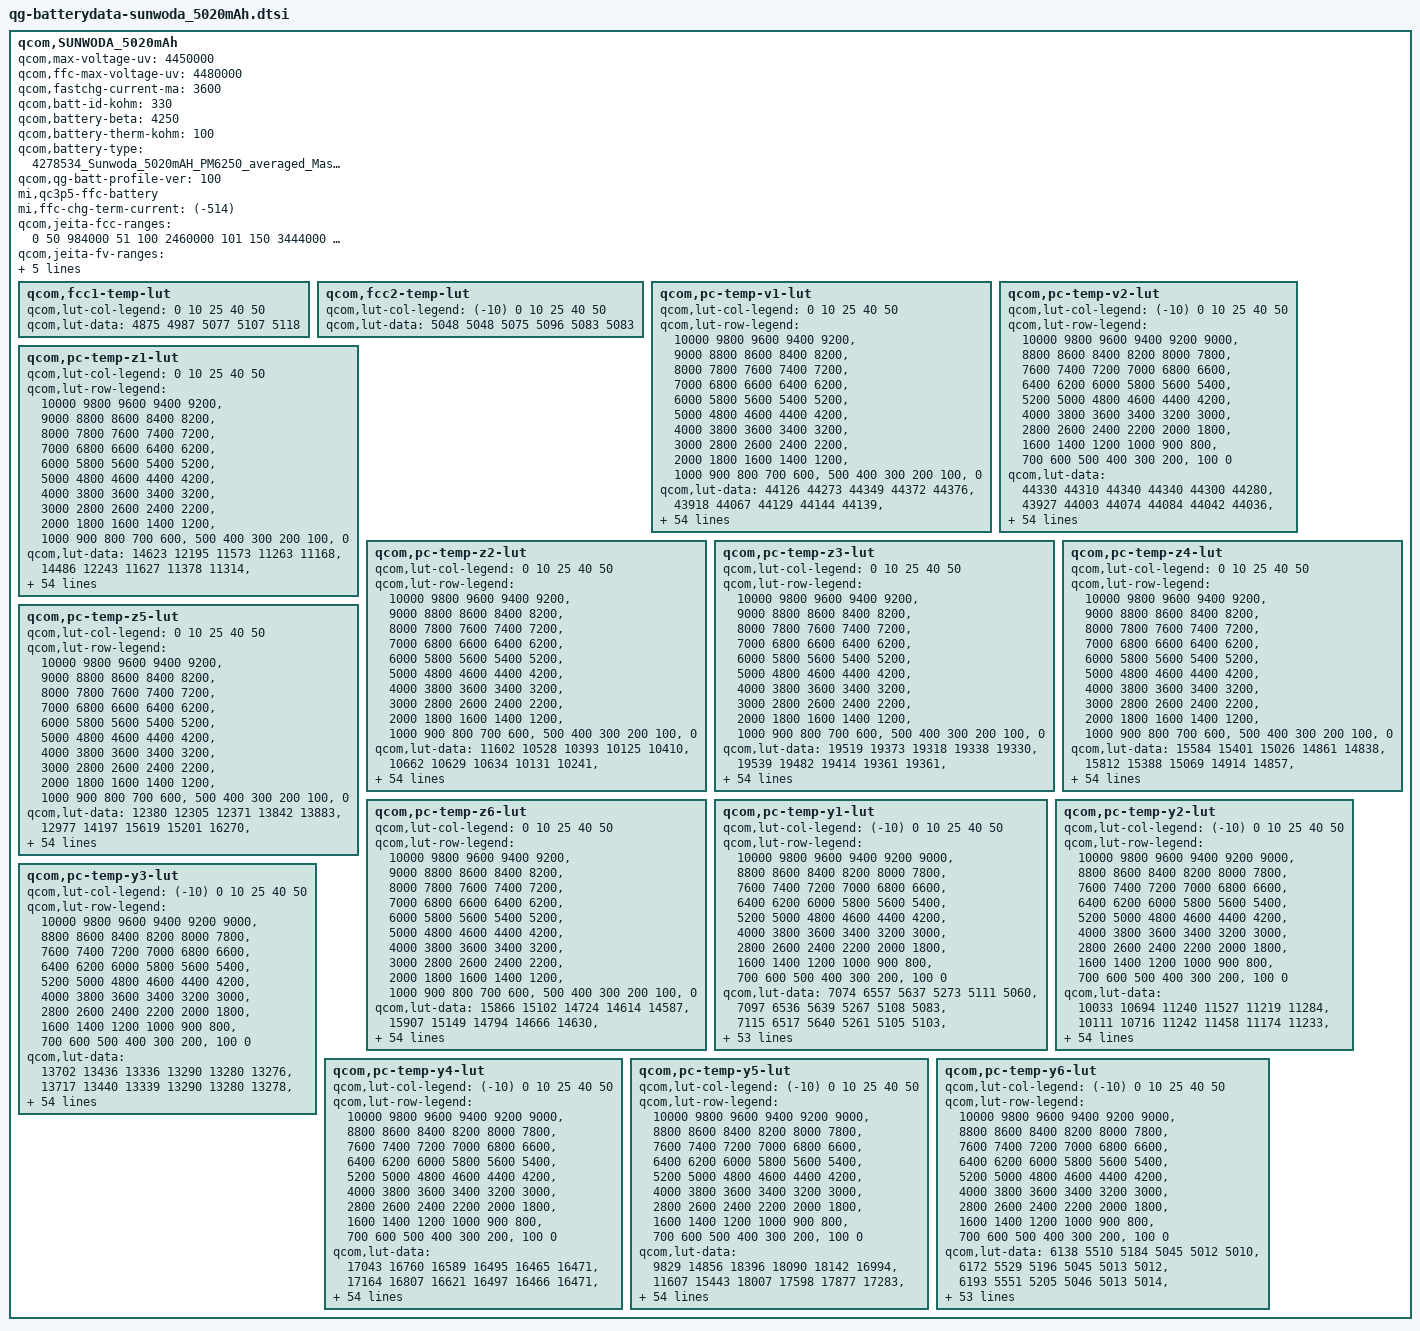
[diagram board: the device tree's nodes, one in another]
/*
 * Copyright (c) 2019, The Linux Foundation. All rights reserved.
 * Copyright (C) 2020 XiaoMi, Inc.
 *
 * This program is free software; you can redistribute it and/or modify
 * it under the terms of the GNU General Public License version 2 and
 * only version 2 as published by the Free Software Foundation.
 *
 * This program is distributed in the hope that it will be useful,
 * but WITHOUT ANY WARRANTY; without even the implied warranty of
 * MERCHANTABILITY or FITNESS FOR A PARTICULAR PURPOSE.  See the
 * GNU General Public License for more details.
 */

qcom,SUNWODA_5020mAh {
	qcom,max-voltage-uv = <4450000>;
	qcom,ffc-max-voltage-uv = <4480000>;
	qcom,fastchg-current-ma = <3600>;
	qcom,batt-id-kohm = <330>;
	qcom,battery-beta = <4250>;
	qcom,battery-therm-kohm = <100>;
	qcom,battery-type =
		"4278534_Sunwoda_5020mAH_PM6250_averaged_MasterSlave_Nov7th2019";
	qcom,qg-batt-profile-ver = <100>;
	mi,qc3p5-ffc-battery;
	mi,ffc-chg-term-current = <(-514)>;
	qcom,jeita-fcc-ranges = <0   50   984000
				 51  100  2460000
				 101 150  3444000
				 151 450  3600000
				 451 600  2460000>;

	qcom,jeita-fv-ranges = <0   50   4450000
				51  100  4450000
				101 150  4450000
				151 450  4480000
				451 600  4100000>;

	qcom,step-chg-ranges = <3001000  4250000  3600000
				4250001  4430000  3300000
				4430001  4450000  3000000>;

	qcom,dynamic-fv-ranges = <0   100  4480000
				 101  200  4460000
				 201  300  4440000
				 301  400  4420000
				 401  500  4400000>;

	qcom,fcc1-temp-lut {
		qcom,lut-col-legend = <0 10 25 40 50>;
		qcom,lut-data = <4875 4987 5077 5107 5118>;
	};

	qcom,fcc2-temp-lut {
		qcom,lut-col-legend = <(-10) 0 10 25 40 50>;
		qcom,lut-data = <5048 5048 5075 5096 5083 5083>;
	};

	qcom,pc-temp-v1-lut {
		qcom,lut-col-legend = <0 10 25 40 50>;
		qcom,lut-row-legend = <10000 9800 9600 9400 9200>,
			<9000 8800 8600 8400 8200>,
			<8000 7800 7600 7400 7200>,
			<7000 6800 6600 6400 6200>,
			<6000 5800 5600 5400 5200>,
			<5000 4800 4600 4400 4200>,
			<4000 3800 3600 3400 3200>,
			<3000 2800 2600 2400 2200>,
			<2000 1800 1600 1400 1200>,
			<1000 900 800 700 600>,
			<500 400 300 200 100>,
			<0>;
		qcom,lut-data = <44126 44273 44349 44372 44376>,
			<43918 44067 44129 44144 44139>,
			<43695 43855 43919 43935 43931>,
			<43465 43639 43710 43727 43728>,
			<43230 43417 43501 43516 43512>,
			<42988 43184 43286 43302 43291>,
			<42744 42939 43049 43072 43061>,
			<42498 42693 42795 42824 42822>,
			<42252 42446 42544 42574 42579>,
			<42013 42199 42296 42327 42334>,
			<41782 41958 42050 42081 42088>,
			<41556 41720 41807 41842 41847>,
			<41335 41488 41567 41609 41609>,
			<41120 41263 41335 41378 41374>,
			<40908 41043 41113 41149 41144>,
			<40698 40830 40898 40926 40919>,
			<40493 40621 40689 40712 40706>,
			<40296 40421 40484 40506 40503>,
			<40106 40238 40290 40310 40309>,
			<39928 40063 40112 40131 40128>,
			<39770 39884 39929 39951 39949>,
			<39617 39705 39710 39731 39735>,
			<39445 39512 39472 39476 39483>,
			<39248 39258 39256 39255 39262>,
			<39054 38973 39052 39074 39089>,
			<38874 38801 38881 38920 38940>,
			<38706 38712 38766 38798 38807>,
			<38596 38643 38674 38697 38688>,
			<38528 38574 38587 38598 38581>,
			<38474 38510 38503 38496 38484>,
			<38425 38450 38424 38400 38395>,
			<38381 38392 38349 38320 38312>,
			<38340 38338 38278 38248 38236>,
			<38300 38287 38217 38181 38163>,
			<38262 38240 38167 38117 38095>,
			<38225 38196 38118 38056 38029>,
			<38190 38160 38069 37997 37962>,
			<38148 38121 38019 37940 37895>,
			<38086 38059 37952 37868 37814>,
			<38004 37966 37863 37773 37711>,
			<37903 37859 37759 37666 37595>,
			<37771 37737 37644 37551 37474>,
			<37623 37595 37511 37420 37341>,
			<37456 37419 37342 37256 37179>,
			<37295 37259 37190 37112 37043>,
			<37218 37158 37097 37029 36966>,
			<37176 37125 37068 36999 36938>,
			<37146 37105 37051 36981 36920>,
			<37114 37079 37029 36962 36899>,
			<37067 37036 36978 36900 36825>,
			<36878 36824 36732 36626 36534>,
			<36429 36373 36289 36175 36087>,
			<35839 35781 35699 35585 35503>,
			<35031 34967 34886 34776 34682>,
			<33735 33660 33609 33497 33378>,
			<30000 30000 30000 30000 30000>;
	};

	qcom,pc-temp-v2-lut {
		qcom,lut-col-legend = <(-10) 0 10 25 40 50>;
		qcom,lut-row-legend = <10000 9800 9600 9400 9200 9000>,
			<8800 8600 8400 8200 8000 7800>,
			<7600 7400 7200 7000 6800 6600>,
			<6400 6200 6000 5800 5600 5400>,
			<5200 5000 4800 4600 4400 4200>,
			<4000 3800 3600 3400 3200 3000>,
			<2800 2600 2400 2200 2000 1800>,
			<1600 1400 1200 1000 900 800>,
			<700 600 500 400 300 200>,
			<100 0>;
		qcom,lut-data = <44330 44310 44340 44340 44300 44280>,
			<43927 44003 44074 44084 44042 44036>,
			<43573 43720 43820 43839 43796 43800>,
			<43276 43463 43584 43608 43564 43573>,
			<43033 43236 43367 43393 43348 43357>,
			<42792 43005 43143 43171 43126 43134>,
			<42532 42756 42903 42933 42888 42896>,
			<42266 42500 42655 42688 42645 42651>,
			<41979 42242 42406 42441 42400 42406>,
			<41652 41981 42155 42192 42154 42159>,
			<41411 41722 41906 41946 41910 41914>,
			<41304 41459 41664 41703 41669 41673>,
			<41220 41208 41425 41463 41432 41435>,
			<41051 41015 41191 41229 41200 41204>,
			<40719 40871 40963 41002 40975 40979>,
			<40359 40705 40745 40781 40756 40760>,
			<40020 40441 40547 40566 40543 40547>,
			<39692 40131 40353 40359 40337 40341>,
			<39430 39869 40142 40164 40145 40149>,
			<39220 39641 39918 39981 39965 39970>,
			<39014 39421 39689 39778 39772 39775>,
			<38767 39200 39447 39533 39544 39545>,
			<38532 38985 39211 39286 39310 39308>,
			<38396 38792 39009 39075 39099 39098>,
			<38311 38614 38829 38885 38900 38901>,
			<38242 38448 38672 38726 38735 38738>,
			<38179 38275 38536 38594 38604 38606>,
			<38123 38120 38414 38479 38490 38492>,
			<38067 38036 38305 38373 38386 38388>,
			<38012 37986 38206 38277 38291 38292>,
			<37958 37944 38112 38188 38205 38206>,
			<37903 37904 38014 38105 38127 38129>,
			<37846 37867 37927 38028 38053 38055>,
			<37784 37823 37865 37957 37978 37980>,
			<37718 37775 37818 37890 37902 37905>,
			<37649 37723 37773 37820 37818 37821>,
			<37580 37669 37733 37747 37722 37723>,
			<37508 37611 37690 37670 37622 37619>,
			<37425 37539 37631 37590 37529 37523>,
			<37331 37451 37556 37505 37438 37428>,
			<37236 37350 37464 37415 37345 37333>,
			<37141 37232 37346 37319 37252 37238>,
			<37051 37106 37212 37199 37138 37126>,
			<36971 36985 37063 37052 36989 36980>,
			<36896 36880 36916 36930 36882 36874>,
			<36816 36784 36825 36879 36838 36832>,
			<36766 36726 36792 36866 36826 36817>,
			<36714 36661 36752 36846 36809 36799>,
			<36652 36595 36694 36811 36779 36765>,
			<36541 36493 36585 36722 36670 36647>,
			<36311 36322 36340 36407 36337 36307>,
			<35881 35966 35877 35885 35817 35764>,
			<35225 35364 35210 35200 35133 35048>,
			<34250 34460 34293 34227 34159 34056>,
			<32677 32962 32764 32652 32768 32603>,
			<30163 28489 27415 27358 27428 27387>;
	};

	qcom,pc-temp-z1-lut {
		qcom,lut-col-legend = <0 10 25 40 50>;
		qcom,lut-row-legend = <10000 9800 9600 9400 9200>,
			<9000 8800 8600 8400 8200>,
			<8000 7800 7600 7400 7200>,
			<7000 6800 6600 6400 6200>,
			<6000 5800 5600 5400 5200>,
			<5000 4800 4600 4400 4200>,
			<4000 3800 3600 3400 3200>,
			<3000 2800 2600 2400 2200>,
			<2000 1800 1600 1400 1200>,
			<1000 900 800 700 600>,
			<500 400 300 200 100>,
			<0>;
		qcom,lut-data = <14623 12195 11573 11263 11168>,
			<14486 12243 11627 11378 11314>,
			<14380 12270 11651 11398 11330>,
			<14290 12279 11656 11404 11336>,
			<14211 12285 11653 11405 11339>,
			<14141 12280 11647 11405 11341>,
			<14088 12253 11641 11405 11341>,
			<14054 12230 11633 11405 11341>,
			<14028 12223 11626 11404 11341>,
			<14005 12217 11620 11405 11344>,
			<13984 12208 11616 11406 11350>,
			<13966 12193 11614 11406 11351>,
			<13949 12179 11614 11404 11349>,
			<13934 12170 11613 11403 11349>,
			<13924 12162 11612 11403 11349>,
			<13920 12154 11611 11403 11349>,
			<13915 12145 11611 11403 11349>,
			<13902 12140 11610 11404 11350>,
			<13874 12140 11611 11405 11351>,
			<13852 12141 11612 11406 11353>,
			<13841 12141 11614 11408 11354>,
			<13833 12145 11615 11408 11355>,
			<13834 12150 11617 11408 11355>,
			<13847 12158 11619 11408 11355>,
			<13859 12170 11622 11410 11358>,
			<13862 12176 11625 11412 11361>,
			<13865 12179 11629 11415 11363>,
			<13868 12181 11634 11419 11365>,
			<13873 12181 11638 11423 11367>,
			<13876 12181 11643 11426 11370>,
			<13872 12181 11647 11429 11374>,
			<13859 12189 11652 11433 11378>,
			<13852 12200 11656 11438 11382>,
			<13855 12206 11661 11442 11385>,
			<13861 12211 11667 11445 11388>,
			<13867 12217 11673 11449 11391>,
			<13875 12223 11677 11452 11394>,
			<13885 12231 11682 11457 11397>,
			<13913 12242 11688 11460 11399>,
			<13949 12256 11695 11464 11401>,
			<13959 12266 11704 11468 11403>,
			<13958 12269 11711 11473 11406>,
			<13961 12274 11720 11478 11410>,
			<14008 12306 11731 11481 11413>,
			<14040 12317 11748 11487 11417>,
			<13998 12339 11752 11491 11419>,
			<14028 12343 11755 11493 11418>,
			<14035 12318 11755 11494 11420>,
			<14025 12336 11757 11494 11420>,
			<14042 12326 11761 11499 11424>,
			<14046 12369 11772 11506 11430>,
			<14079 12384 11785 11513 11435>,
			<14074 12382 11802 11522 11443>,
			<14115 12400 11812 11535 11455>,
			<14115 12400 11812 11535 11455>,
			<14115 12400 11812 11535 11455>;
	};

	qcom,pc-temp-z2-lut {
		qcom,lut-col-legend = <0 10 25 40 50>;
		qcom,lut-row-legend = <10000 9800 9600 9400 9200>,
			<9000 8800 8600 8400 8200>,
			<8000 7800 7600 7400 7200>,
			<7000 6800 6600 6400 6200>,
			<6000 5800 5600 5400 5200>,
			<5000 4800 4600 4400 4200>,
			<4000 3800 3600 3400 3200>,
			<3000 2800 2600 2400 2200>,
			<2000 1800 1600 1400 1200>,
			<1000 900 800 700 600>,
			<500 400 300 200 100>,
			<0>;
		qcom,lut-data = <11602 10528 10393 10125 10410>,
			<10662 10629 10634 10131 10241>,
			<10584 10668 10665 10286 10330>,
			<10547 10648 10742 10537 10403>,
			<10517 10609 11146 11112 10435>,
			<10493 10574 11534 11840 10456>,
			<10471 10538 11357 11855 10456>,
			<10437 10506 10777 11027 10417>,
			<10406 10476 10514 10455 10385>,
			<10400 10453 10479 10430 10388>,
			<10406 10450 10462 10418 10394>,
			<10416 10459 10471 10555 10393>,
			<10430 10473 10506 11248 10376>,
			<10449 10501 10579 11725 10363>,
			<10461 10543 10897 11801 10388>,
			<10465 10570 11228 11851 10429>,
			<10469 10588 11347 11944 10413>,
			<10487 10605 11423 12086 10290>,
			<10533 10633 11410 12138 10212>,
			<10574 10662 11028 11385 10230>,
			<10595 10670 10678 10444 10272>,
			<10613 10668 10707 10421 10374>,
			<10633 10666 10803 10720 10616>,
			<10653 10682 10826 10852 10737>,
			<10672 10718 10747 10644 10602>,
			<10690 10730 10678 10409 10430>,
			<10706 10715 10684 10394 10526>,
			<10714 10702 10707 10418 10936>,
			<10718 10709 10739 10464 11124>,
			<10721 10734 10804 10648 10939>,
			<10729 10754 10849 10819 10669>,
			<10743 10770 10846 10769 10486>,
			<10756 10781 10836 10614 10327>,
			<10768 10779 10816 10560 10276>,
			<10779 10771 10761 10560 10273>,
			<10791 10768 10722 10560 10272>,
			<10804 10770 10738 10609 10295>,
			<10819 10776 10782 10722 10367>,
			<10839 10793 10832 10773 10443>,
			<10864 10832 10905 10788 10527>,
			<10891 10861 10949 10796 10604>,
			<10921 10870 10920 10801 10664>,
			<10967 10882 10884 10804 10702>,
			<11056 10936 10902 10790 10648>,
			<11545 11198 10985 10783 10569>,
			<10819 11350 11039 10625 10494>,
			<10787 11321 11026 10643 10469>,
			<10662 11367 10977 10544 10495>,
			<10614 11382 10949 10591 10541>,
			<10607 11454 11001 10745 10632>,
			<10576 11397 11101 10574 10458>,
			<10448 11385 10987 10386 10232>,
			<10258 11253 10833 10325 10174>,
			<10119 10993 10776 10313 10100>,
			<10119 10993 10776 10313 10100>,
			<10119 10993 10776 10313 10100>;
	};

	qcom,pc-temp-z3-lut {
		qcom,lut-col-legend = <0 10 25 40 50>;
		qcom,lut-row-legend = <10000 9800 9600 9400 9200>,
			<9000 8800 8600 8400 8200>,
			<8000 7800 7600 7400 7200>,
			<7000 6800 6600 6400 6200>,
			<6000 5800 5600 5400 5200>,
			<5000 4800 4600 4400 4200>,
			<4000 3800 3600 3400 3200>,
			<3000 2800 2600 2400 2200>,
			<2000 1800 1600 1400 1200>,
			<1000 900 800 700 600>,
			<500 400 300 200 100>,
			<0>;
		qcom,lut-data = <19519 19373 19318 19338 19330>,
			<19539 19482 19414 19361 19361>,
			<19616 19546 19449 19383 19373>,
			<19701 19573 19466 19406 19381>,
			<19728 19589 19477 19428 19393>,
			<19738 19597 19483 19447 19405>,
			<19748 19603 19481 19449 19410>,
			<19763 19605 19475 19439 19412>,
			<19778 19604 19471 19430 19413>,
			<19780 19602 19470 19425 19412>,
			<19769 19600 19469 19421 19409>,
			<19756 19596 19465 19423 19406>,
			<19746 19590 19457 19436 19401>,
			<19737 19580 19456 19443 19396>,
			<19734 19567 19468 19440 19394>,
			<19744 19559 19479 19435 19392>,
			<19755 19555 19478 19430 19388>,
			<19750 19551 19471 19425 19380>,
			<19727 19543 19460 19417 19372>,
			<19714 19535 19435 19393 19366>,
			<19716 19532 19415 19368 19361>,
			<19719 19535 19423 19370 19362>,
			<19723 19540 19443 19386 19369>,
			<19730 19552 19448 19392 19373>,
			<19736 19568 19434 19376 19356>,
			<19738 19573 19418 19356 19335>,
			<19739 19562 19409 19350 19346>,
			<19739 19548 19402 19346 19392>,
			<19731 19540 19401 19346 19414>,
			<19720 19535 19405 19377 19411>,
			<19710 19533 19411 19409 19406>,
			<19701 19537 19424 19409 19400>,
			<19694 19543 19442 19404 19392>,
			<19689 19546 19446 19399 19384>,
			<19684 19549 19440 19393 19375>,
			<19681 19550 19434 19387 19367>,
			<19677 19546 19429 19380 19360>,
			<19673 19539 19424 19374 19355>,
			<19667 19535 19420 19370 19352>,
			<19657 19530 19417 19367 19349>,
			<19647 19524 19414 19365 19348>,
			<19634 19516 19409 19365 19353>,
			<19616 19505 19403 19366 19362>,
			<19584 19493 19401 19368 19367>,
			<19510 19455 19393 19367 19366>,
			<19321 19429 19374 19345 19345>,
			<19316 19428 19372 19345 19341>,
			<19306 19414 19364 19338 19332>,
			<19303 19412 19366 19334 19321>,
			<19301 19395 19353 19324 19324>,
			<19304 19317 19351 19345 19352>,
			<19309 19312 19350 19363 19358>,
			<19312 19308 19342 19362 19351>,
			<19318 19301 19343 19349 19358>,
			<19318 19301 19343 19349 19358>,
			<19318 19301 19343 19349 19358>;
	};

	qcom,pc-temp-z4-lut {
		qcom,lut-col-legend = <0 10 25 40 50>;
		qcom,lut-row-legend = <10000 9800 9600 9400 9200>,
			<9000 8800 8600 8400 8200>,
			<8000 7800 7600 7400 7200>,
			<7000 6800 6600 6400 6200>,
			<6000 5800 5600 5400 5200>,
			<5000 4800 4600 4400 4200>,
			<4000 3800 3600 3400 3200>,
			<3000 2800 2600 2400 2200>,
			<2000 1800 1600 1400 1200>,
			<1000 900 800 700 600>,
			<500 400 300 200 100>,
			<0>;
		qcom,lut-data = <15584 15401 15026 14861 14838>,
			<15812 15388 15069 14914 14857>,
			<15731 15358 15036 14900 14851>,
			<15598 15286 14995 14879 14841>,
			<15490 15185 14929 14832 14826>,
			<15385 15109 14870 14775 14804>,
			<15291 15045 14851 14763 14785>,
			<15209 14992 14842 14767 14769>,
			<15139 14951 14830 14769 14753>,
			<15087 14916 14808 14760 14736>,
			<15049 14884 14785 14739 14720>,
			<15018 14856 14769 14715 14713>,
			<14990 14832 14755 14681 14710>,
			<14965 14812 14735 14659 14707>,
			<14938 14795 14699 14652 14701>,
			<14901 14784 14670 14647 14695>,
			<14872 14778 14662 14643 14691>,
			<14869 14773 14657 14639 14690>,
			<14870 14767 14658 14637 14687>,
			<14870 14761 14675 14651 14683>,
			<14844 14759 14698 14677 14678>,
			<14805 14758 14715 14702 14685>,
			<14797 14758 14732 14731 14724>,
			<14805 14789 14758 14762 14763>,
			<14816 14859 14812 14804 14798>,
			<14840 14883 14851 14836 14825>,
			<14873 14881 14851 14837 14811>,
			<14884 14876 14846 14827 14748>,
			<14878 14869 14839 14812 14710>,
			<14869 14858 14822 14768 14700>,
			<14860 14844 14800 14722 14693>,
			<14847 14826 14773 14707 14688>,
			<14835 14807 14745 14699 14684>,
			<14822 14793 14731 14695 14682>,
			<14810 14781 14724 14692 14681>,
			<14799 14772 14720 14691 14680>,
			<14789 14765 14721 14692 14681>,
			<14779 14760 14721 14694 14683>,
			<14772 14760 14723 14698 14686>,
			<14766 14761 14732 14710 14701>,
			<14761 14762 14739 14720 14713>,
			<14756 14755 14735 14717 14705>,
			<14750 14744 14728 14710 14693>,
			<14743 14733 14722 14707 14692>,
			<14727 14707 14701 14693 14684>,
			<14878 14691 14686 14687 14673>,
			<14882 14687 14680 14678 14670>,
			<14885 14687 14671 14670 14661>,
			<14883 14679 14653 14651 14648>,
			<14879 14691 14662 14651 14635>,
			<14881 14794 14690 14668 14653>,
			<14894 14811 14702 14662 14661>,
			<14899 14818 14714 14667 14670>,
			<14905 14829 14715 14681 14665>,
			<14905 14829 14715 14681 14665>,
			<14905 14829 14715 14681 14665>;
	};

	qcom,pc-temp-z5-lut {
		qcom,lut-col-legend = <0 10 25 40 50>;
		qcom,lut-row-legend = <10000 9800 9600 9400 9200>,
			<9000 8800 8600 8400 8200>,
			<8000 7800 7600 7400 7200>,
			<7000 6800 6600 6400 6200>,
			<6000 5800 5600 5400 5200>,
			<5000 4800 4600 4400 4200>,
			<4000 3800 3600 3400 3200>,
			<3000 2800 2600 2400 2200>,
			<2000 1800 1600 1400 1200>,
			<1000 900 800 700 600>,
			<500 400 300 200 100>,
			<0>;
		qcom,lut-data = <12380 12305 12371 13842 13883>,
			<12977 14197 15619 15201 16270>,
			<13837 15384 17310 16724 17379>,
			<14663 15924 17769 18365 18242>,
			<15087 16298 17757 20169 19687>,
			<15319 16681 17744 21804 21321>,
			<15608 17037 17837 22069 22392>,
			<16266 17416 18167 21780 22993>,
			<17068 17845 18548 21585 23612>,
			<17462 18325 18974 21899 24827>,
			<17622 18896 19503 22737 26192>,
			<17781 19603 20117 24711 26482>,
			<18027 20334 20910 30109 26371>,
			<18369 20997 22378 34722 26292>,
			<18979 21664 27047 37013 27473>,
			<21154 22488 31800 38814 29440>,
			<23299 23672 33813 40828 29572>,
			<23361 24407 35162 43045 28187>,
			<22724 24211 35061 43835 27319>,
			<22369 23799 29831 35570 27617>,
			<23825 23917 25050 25235 28344>,
			<27103 26700 30356 26559 29918>,
			<31974 30989 42865 35316 33453>,
			<41520 37206 46057 39135 35144>,
			<48654 45003 37032 30818 27737>,
			<50069 46897 27397 20616 18291>,
			<50869 39943 23460 17824 18701>,
			<50766 32164 20782 16420 24241>,
			<46710 29275 20203 16232 27411>,
			<41669 27413 20294 20086 28019>,
			<39037 26938 20487 24649 28399>,
			<37038 27881 22957 26167 28785>,
			<36308 29506 27968 27019 29135>,
			<36453 31720 30500 28085 29238>,
			<36778 34838 31553 29814 29119>,
			<37367 36532 32396 31007 28908>,
			<38719 37104 33448 30956 28649>,
			<39984 37411 34377 30630 28257>,
			<40800 37429 34391 30050 27588>,
			<41436 37381 32872 28399 25800>,
			<41429 37254 30757 26431 24417>,
			<39690 34762 27781 24508 24969>,
			<37249 32338 25505 23154 26406>,
			<33924 31555 25793 23914 28197>,
			<30516 32054 27004 25280 28621>,
			<13910 30003 24742 20396 22021>,
			<13646 29382 24872 20707 20644>,
			<13265 24832 23331 20184 19430>,
			<13152 24882 26590 21764 20339>,
			<13120 21615 22378 20039 23880>,
			<13226 13966 18554 20412 25874>,
			<13138 13451 16574 21809 22649>,
			<12992 13139 15300 19864 18577>,
			<12875 12696 14952 16121 18210>,
			<12875 12696 14952 16121 18210>,
			<12875 12696 14952 16121 18210>;
	};

	qcom,pc-temp-z6-lut {
		qcom,lut-col-legend = <0 10 25 40 50>;
		qcom,lut-row-legend = <10000 9800 9600 9400 9200>,
			<9000 8800 8600 8400 8200>,
			<8000 7800 7600 7400 7200>,
			<7000 6800 6600 6400 6200>,
			<6000 5800 5600 5400 5200>,
			<5000 4800 4600 4400 4200>,
			<4000 3800 3600 3400 3200>,
			<3000 2800 2600 2400 2200>,
			<2000 1800 1600 1400 1200>,
			<1000 900 800 700 600>,
			<500 400 300 200 100>,
			<0>;
		qcom,lut-data = <15866 15102 14724 14614 14587>,
			<15907 15149 14794 14666 14630>,
			<15869 15164 14805 14676 14638>,
			<15804 15140 14806 14680 14641>,
			<15746 15095 14787 14675 14640>,
			<15682 15060 14762 14664 14638>,
			<15627 15028 14749 14657 14636>,
			<15584 14999 14741 14653 14631>,
			<15548 14975 14731 14648 14625>,
			<15514 14953 14720 14640 14618>,
			<15483 14934 14709 14631 14610>,
			<15456 14917 14699 14623 14605>,
			<15432 14901 14689 14617 14600>,
			<15411 14884 14680 14611 14596>,
			<15394 14869 14673 14606 14592>,
			<15379 14859 14666 14601 14588>,
			<15366 14853 14660 14596 14584>,
			<15354 14848 14654 14591 14578>,
			<15342 14841 14650 14587 14573>,
			<15330 14834 14645 14581 14567>,
			<15314 14832 14642 14576 14562>,
			<15299 14834 14649 14582 14567>,
			<15297 14837 14668 14606 14589>,
			<15304 14858 14684 14623 14605>,
			<15313 14898 14700 14630 14609>,
			<15326 14911 14709 14635 14612>,
			<15343 14905 14707 14633 14612>,
			<15348 14897 14701 14627 14610>,
			<15342 14891 14696 14623 14607>,
			<15334 14885 14692 14620 14602>,
			<15326 14880 14688 14618 14597>,
			<15317 14875 14685 14613 14592>,
			<15309 14871 14682 14608 14587>,
			<15302 14868 14679 14603 14582>,
			<15297 14865 14673 14599 14577>,
			<15292 14863 14669 14596 14573>,
			<15289 14859 14667 14593 14569>,
			<15287 14856 14665 14591 14567>,
			<15286 14856 14665 14591 14566>,
			<15286 14858 14668 14594 14571>,
			<15285 14859 14671 14597 14575>,
			<15284 14855 14668 14596 14575>,
			<15283 14850 14663 14594 14575>,
			<15275 14846 14661 14594 14577>,
			<15240 14826 14651 14589 14573>,
			<15218 14810 14637 14575 14559>,
			<15217 14807 14633 14571 14555>,
			<15214 14801 14625 14564 14547>,
			<15214 14798 14618 14554 14535>,
			<15216 14798 14617 14549 14531>,
			<15227 14807 14631 14569 14554>,
			<15243 14818 14639 14578 14564>,
			<15257 14826 14643 14583 14567>,
			<15279 14838 14648 14585 14571>,
			<15279 14838 14648 14585 14571>,
			<15279 14838 14648 14585 14571>;
	};

	qcom,pc-temp-y1-lut {
		qcom,lut-col-legend = <(-10) 0 10 25 40 50>;
		qcom,lut-row-legend = <10000 9800 9600 9400 9200 9000>,
			<8800 8600 8400 8200 8000 7800>,
			<7600 7400 7200 7000 6800 6600>,
			<6400 6200 6000 5800 5600 5400>,
			<5200 5000 4800 4600 4400 4200>,
			<4000 3800 3600 3400 3200 3000>,
			<2800 2600 2400 2200 2000 1800>,
			<1600 1400 1200 1000 900 800>,
			<700 600 500 400 300 200>,
			<100 0>;
		qcom,lut-data = <7074 6557 5637 5273 5111 5060>,
			<7097 6536 5639 5267 5108 5083>,
			<7115 6517 5640 5261 5105 5103>,
			<7126 6501 5638 5256 5101 5120>,
			<7133 6490 5636 5252 5097 5131>,
			<7135 6486 5634 5248 5096 5135>,
			<7130 6491 5630 5244 5095 5131>,
			<7121 6499 5625 5241 5095 5124>,
			<7118 6500 5621 5238 5095 5115>,
			<7117 6500 5616 5235 5094 5103>,
			<7117 6500 5612 5232 5093 5097>,
			<7118 6500 5607 5230 5090 5097>,
			<7121 6500 5601 5228 5087 5098>,
			<7121 6498 5597 5227 5087 5097>,
			<7116 6487 5594 5226 5088 5095>,
			<7108 6479 5592 5224 5089 5094>,
			<7090 6488 5593 5223 5089 5095>,
			<7068 6504 5594 5221 5090 5096>,
			<7067 6514 5597 5222 5090 5096>,
			<7087 6521 5601 5224 5090 5096>,
			<7105 6525 5603 5226 5091 5097>,
			<7115 6522 5600 5228 5093 5098>,
			<7122 6519 5598 5230 5095 5099>,
			<7121 6520 5599 5232 5095 5099>,
			<7108 6528 5604 5234 5095 5099>,
			<7093 6533 5611 5236 5095 5099>,
			<7077 6530 5618 5239 5097 5101>,
			<7063 6523 5625 5242 5100 5104>,
			<7062 6518 5629 5245 5102 5106>,
			<7070 6513 5631 5248 5104 5107>,
			<7075 6508 5634 5251 5106 5109>,
			<7074 6502 5638 5256 5109 5112>,
			<7073 6496 5642 5262 5112 5115>,
			<7074 6493 5641 5267 5114 5117>,
			<7078 6492 5636 5273 5117 5120>,
			<7082 6491 5635 5279 5119 5122>,
			<7085 6504 5644 5284 5121 5124>,
			<7087 6524 5658 5288 5124 5126>,
			<7083 6526 5667 5291 5127 5128>,
			<7063 6519 5675 5293 5131 5130>,
			<7051 6511 5681 5296 5132 5131>,
			<7060 6501 5685 5300 5132 5130>,
			<7069 6495 5689 5305 5132 5131>,
			<7054 6509 5692 5312 5135 5135>,
			<7030 6500 5706 5322 5141 5139>,
			<7080 6533 5691 5326 5144 5138>,
			<7033 6532 5703 5332 5144 5136>,
			<7033 6545 5704 5331 5142 5134>,
			<7080 6535 5710 5334 5142 5132>,
			<7098 6535 5709 5330 5141 5132>,
			<7053 6510 5690 5331 5144 5134>,
			<7184 6543 5687 5342 5149 5137>,
			<7190 6536 5700 5366 5156 5130>,
			<7035 6602 5740 5392 5166 5129>,
			<7035 6602 5740 5392 5166 5129>,
			<7035 6602 5740 5392 5166 5129>;
	};

	qcom,pc-temp-y2-lut {
		qcom,lut-col-legend = <(-10) 0 10 25 40 50>;
		qcom,lut-row-legend = <10000 9800 9600 9400 9200 9000>,
			<8800 8600 8400 8200 8000 7800>,
			<7600 7400 7200 7000 6800 6600>,
			<6400 6200 6000 5800 5600 5400>,
			<5200 5000 4800 4600 4400 4200>,
			<4000 3800 3600 3400 3200 3000>,
			<2800 2600 2400 2200 2000 1800>,
			<1600 1400 1200 1000 900 800>,
			<700 600 500 400 300 200>,
			<100 0>;
		qcom,lut-data = <10033 10694 11240 11527 11219 11284>,
			<10111 10716 11242 11458 11174 11233>,
			<10184 10762 11238 11366 11104 11151>,
			<10254 10816 11229 11275 11027 11062>,
			<10320 10861 11216 11206 10967 10988>,
			<10380 10881 11199 11180 10944 10953>,
			<10430 10882 11176 11192 10950 10947>,
			<10479 10883 11151 11210 10958 10944>,
			<10568 10878 11137 11201 10954 10918>,
			<10734 10850 11127 11156 10926 10837>,
			<10828 10832 11123 11131 10892 10793>,
			<10770 10940 11131 11150 10849 10831>,
			<10680 11107 11148 11183 10811 10900>,
			<10707 11119 11166 11212 10827 10959>,
			<10952 11012 11188 11240 10918 11019>,
			<11111 10943 11218 11271 11001 11046>,
			<10632 11030 11264 11305 11049 11048>,
			<9881 11182 11321 11347 11093 11049>,
			<9713 11254 11379 11426 11147 11078>,
			<9697 11288 11443 11549 11210 11189>,
			<9688 11320 11478 11598 11281 11283>,
			<9682 11371 11487 11579 11386 11345>,
			<9678 11416 11493 11553 11472 11387>,
			<9675 11397 11497 11535 11438 11371>,
			<9672 11255 11499 11519 11298 11306>,
			<9671 11162 11503 11514 11234 11270>,
			<9670 11160 11551 11516 11245 11263>,
			<9669 11160 11610 11521 11269 11259>,
			<9668 11047 11629 11542 11341 11323>,
			<9667 10438 11638 11597 11499 11526>,
			<9666 9961 11641 11656 11592 11637>,
			<9666 9835 11631 11733 11626 11665>,
			<9666 9758 11612 11786 11644 11680>,
			<9665 9721 11577 11785 11623 11661>,
			<9665 9699 11513 11773 11560 11596>,
			<9664 9686 11453 11758 11535 11538>,
			<9664 9678 11409 11733 11542 11499>,
			<9663 9673 11362 11698 11549 11458>,
			<9663 9669 11286 11640 11504 11392>,
			<9663 9666 11178 11568 11387 11310>,
			<9663 9664 11069 11551 11348 11284>,
			<9663 9663 10970 11562 11404 11293>,
			<9662 9662 10855 11557 11410 11282>,
			<9661 9661 10715 11489 11219 11149>,
			<9660 9660 10056 11313 11155 11167>,
			<9660 9659 9981 11299 11021 10965>,
			<9659 9659 9900 11247 11077 10985>,
			<9658 9658 9822 11221 11052 11023>,
			<9656 9657 9774 11191 11083 11009>,
			<9655 9657 9746 11225 11058 11059>,
			<9652 9656 9714 11203 10930 11020>,
			<9650 9655 9683 11058 10907 10897>,
			<9650 9652 9664 10931 10848 10730>,
			<9650 9649 9656 10854 10692 10600>,
			<9650 9649 9656 10854 10692 10600>,
			<9650 9649 9656 10854 10692 10600>;
	};

	qcom,pc-temp-y3-lut {
		qcom,lut-col-legend = <(-10) 0 10 25 40 50>;
		qcom,lut-row-legend = <10000 9800 9600 9400 9200 9000>,
			<8800 8600 8400 8200 8000 7800>,
			<7600 7400 7200 7000 6800 6600>,
			<6400 6200 6000 5800 5600 5400>,
			<5200 5000 4800 4600 4400 4200>,
			<4000 3800 3600 3400 3200 3000>,
			<2800 2600 2400 2200 2000 1800>,
			<1600 1400 1200 1000 900 800>,
			<700 600 500 400 300 200>,
			<100 0>;
		qcom,lut-data = <13702 13436 13336 13290 13280 13276>,
			<13717 13440 13339 13290 13280 13278>,
			<13723 13445 13342 13291 13281 13280>,
			<13722 13450 13345 13291 13281 13282>,
			<13716 13454 13348 13292 13282 13284>,
			<13709 13456 13350 13293 13283 13285>,
			<13697 13457 13353 13294 13284 13286>,
			<13680 13457 13355 13296 13285 13286>,
			<13658 13456 13355 13297 13286 13286>,
			<13626 13449 13355 13298 13287 13287>,
			<13595 13445 13355 13298 13287 13287>,
			<13564 13449 13354 13298 13288 13287>,
			<13539 13456 13352 13299 13288 13288>,
			<13535 13452 13350 13300 13289 13290>,
			<13538 13426 13347 13303 13293 13293>,
			<13540 13409 13345 13304 13295 13295>,
			<13519 13410 13345 13304 13295 13294>,
			<13487 13412 13344 13303 13294 13293>,
			<13484 13411 13344 13303 13294 13294>,
			<13500 13402 13343 13304 13296 13297>,
			<13511 13392 13342 13304 13297 13298>,
			<13499 13383 13337 13302 13295 13295>,
			<13479 13374 13331 13299 13291 13290>,
			<13480 13366 13327 13296 13287 13287>,
			<13505 13360 13324 13292 13283 13283>,
			<13537 13352 13322 13289 13281 13281>,
			<13567 13337 13321 13288 13279 13279>,
			<13600 13321 13319 13287 13279 13278>,
			<13634 13319 13318 13288 13279 13278>,
			<13670 13325 13317 13290 13280 13279>,
			<13708 13333 13316 13290 13281 13280>,
			<13752 13347 13316 13290 13281 13281>,
			<13800 13369 13315 13290 13281 13282>,
			<13845 13392 13315 13290 13281 13282>,
			<13889 13418 13317 13290 13281 13282>,
			<13933 13450 13318 13290 13280 13281>,
			<13978 13493 13320 13290 13281 13281>,
			<14021 13545 13323 13291 13281 13280>,
			<14053 13605 13326 13290 13281 13280>,
			<14077 13676 13330 13289 13281 13280>,
			<14101 13750 13333 13289 13282 13280>,
			<14128 13827 13337 13293 13285 13282>,
			<14160 13904 13341 13294 13286 13283>,
			<14202 13977 13348 13292 13281 13280>,
			<14273 14054 13348 13293 13283 13284>,
			<14271 14016 13344 13296 13287 13286>,
			<14357 14086 13359 13303 13292 13291>,
			<14487 14172 13379 13307 13295 13294>,
			<14669 14263 13407 13312 13298 13295>,
			<14964 14340 13441 13316 13295 13294>,
			<15932 14465 13481 13310 13289 13289>,
			<18302 14701 13547 13310 13292 13289>,
			<24419 15638 13743 13318 13297 13292>,
			<41286 18928 14287 13331 13303 13299>,
			<41286 18928 14287 13331 13303 13299>,
			<41286 18928 14287 13331 13303 13299>;
	};

	qcom,pc-temp-y4-lut {
		qcom,lut-col-legend = <(-10) 0 10 25 40 50>;
		qcom,lut-row-legend = <10000 9800 9600 9400 9200 9000>,
			<8800 8600 8400 8200 8000 7800>,
			<7600 7400 7200 7000 6800 6600>,
			<6400 6200 6000 5800 5600 5400>,
			<5200 5000 4800 4600 4400 4200>,
			<4000 3800 3600 3400 3200 3000>,
			<2800 2600 2400 2200 2000 1800>,
			<1600 1400 1200 1000 900 800>,
			<700 600 500 400 300 200>,
			<100 0>;
		qcom,lut-data = <17043 16760 16589 16495 16465 16471>,
			<17164 16807 16621 16497 16466 16471>,
			<17280 16886 16655 16498 16467 16471>,
			<17378 16972 16685 16500 16468 16471>,
			<17446 17042 16706 16502 16469 16471>,
			<17472 17071 16714 16503 16469 16471>,
			<17452 17067 16709 16503 16469 16471>,
			<17413 17060 16699 16503 16468 16472>,
			<17384 17055 16694 16505 16469 16473>,
			<17358 17051 16689 16508 16472 16475>,
			<17346 17046 16687 16513 16476 16478>,
			<17452 17028 16692 16519 16482 16481>,
			<17618 17006 16701 16526 16487 16484>,
			<17614 17027 16712 16533 16489 16487>,
			<17402 17156 16727 16538 16489 16489>,
			<17223 17240 16744 16545 16491 16491>,
			<17166 17164 16775 16561 16498 16500>,
			<17126 17030 16803 16580 16511 16513>,
			<17070 16962 16801 16602 16526 16528>,
			<16996 16927 16773 16628 16547 16547>,
			<16927 16893 16738 16637 16556 16555>,
			<16860 16849 16691 16601 16546 16545>,
			<16806 16803 16641 16552 16529 16528>,
			<16797 16759 16611 16522 16509 16508>,
			<16797 16715 16588 16498 16482 16481>,
			<16797 16677 16576 16491 16471 16470>,
			<16799 16643 16570 16494 16473 16473>,
			<16802 16616 16567 16500 16477 16478>,
			<16808 16616 16565 16504 16482 16483>,
			<16819 16640 16564 16508 16487 16489>,
			<16829 16665 16562 16513 16494 16495>,
			<16836 16682 16545 16520 16506 16505>,
			<16841 16698 16527 16526 16516 16513>,
			<16847 16716 16527 16531 16519 16516>,
			<16856 16737 16537 16535 16520 16518>,
			<16860 16756 16549 16535 16519 16518>,
			<16859 16771 16569 16522 16504 16503>,
			<16859 16784 16591 16509 16486 16486>,
			<16856 16793 16610 16503 16480 16479>,
			<16847 16801 16627 16499 16476 16474>,
			<16841 16804 16637 16499 16476 16473>,
			<16842 16788 16642 16505 16479 16479>,
			<16845 16769 16644 16506 16480 16481>,
			<16861 16765 16640 16501 16468 16467>,
			<16877 16767 16664 16497 16459 16455>,
			<16835 16744 16656 16499 16470 16469>,
			<16851 16762 16677 16509 16489 16489>,
			<16870 16790 16710 16531 16519 16520>,
			<16888 16829 16752 16560 16556 16558>,
			<16912 16878 16798 16585 16550 16548>,
			<17066 16901 16822 16536 16495 16490>,
			<17584 16887 16835 16526 16478 16469>,
			<19908 16966 16877 16548 16480 16472>,
			<36685 17982 16981 16580 16500 16497>,
			<36685 17982 16981 16580 16500 16497>,
			<36685 17982 16981 16580 16500 16497>;
	};

	qcom,pc-temp-y5-lut {
		qcom,lut-col-legend = <(-10) 0 10 25 40 50>;
		qcom,lut-row-legend = <10000 9800 9600 9400 9200 9000>,
			<8800 8600 8400 8200 8000 7800>,
			<7600 7400 7200 7000 6800 6600>,
			<6400 6200 6000 5800 5600 5400>,
			<5200 5000 4800 4600 4400 4200>,
			<4000 3800 3600 3400 3200 3000>,
			<2800 2600 2400 2200 2000 1800>,
			<1600 1400 1200 1000 900 800>,
			<700 600 500 400 300 200>,
			<100 0>;
		qcom,lut-data = <9829 14856 18396 18090 18142 16994>,
			<11607 15443 18007 17598 17877 17283>,
			<13527 16045 17756 17002 17584 17409>,
			<15371 16612 17614 16405 17300 17409>,
			<16920 17093 17552 15913 17063 17320>,
			<17954 17440 17538 15629 16912 17179>,
			<18617 17698 17646 15522 16847 16836>,
			<19057 17879 17803 15444 16795 16382>,
			<18913 17818 17757 15307 16642 16120>,
			<17799 17330 17362 15101 16262 15957>,
			<17076 17002 16891 14858 15853 15777>,
			<17700 16986 16420 14484 15401 15462>,
			<19124 16979 15926 14157 15030 15178>,
			<21052 17051 15469 14186 15169 15299>,
			<24287 17524 15001 14425 15916 15931>,
			<26094 18171 14808 14538 16306 16261>,
			<22565 19029 15613 14300 15684 15587>,
			<17081 20046 17125 14019 14890 14728>,
			<16291 20838 18681 14242 14836 14694>,
			<17703 21499 20546 15298 15070 15061>,
			<18621 22032 21751 16703 15507 15666>,
			<16533 22413 22340 19348 17959 17781>,
			<13290 22738 22686 21607 20653 19979>,
			<12661 23162 22595 21295 20595 20030>,
			<12661 23737 22140 19740 19273 19282>,
			<12662 24036 21912 18511 17968 18362>,
			<12746 20377 21986 17617 16670 16914>,
			<12892 14616 22146 17074 15732 15706>,
			<12960 13253 22526 17360 15750 15651>,
			<12988 13061 23307 18246 16075 15848>,
			<13030 12995 23653 18823 16346 16115>,
			<13208 13259 23641 19069 16489 16547>,
			<13457 13692 23611 19308 16646 17104>,
			<13570 13833 23076 19707 16966 17710>,
			<13615 13867 21311 20226 17525 18403>,
			<13678 13915 19967 20726 18255 19054>,
			<13935 14173 19262 21291 19580 19770>,
			<14255 14511 18720 21638 20627 20249>,
			<14288 14552 18256 20686 20434 19694>,
			<14119 14432 17858 18676 19781 18176>,
			<13884 14353 17620 18139 19619 17690>,
			<13546 14424 17506 18388 20610 18635>,
			<13213 14495 17396 18313 20764 18937>,
			<13003 14299 17267 17407 18093 17737>,
			<13036 14119 14643 17057 17929 18428>,
			<13305 14104 13912 16823 16860 16864>,
			<13139 13827 14052 17917 17335 17224>,
			<13266 13827 14137 17623 17124 16982>,
			<13689 14359 14494 18012 17185 16495>,
			<13733 14403 15304 18797 16515 16344>,
			<12588 15042 15573 19061 16302 16587>,
			<10912 14283 14781 18152 17698 16680>,
			<9634 12526 13725 19105 19248 16520>,
			<8968 10281 12959 20778 23195 22815>,
			<8968 10281 12959 20778 23195 22815>,
			<8968 10281 12959 20778 23195 22815>;
	};

	qcom,pc-temp-y6-lut {
		qcom,lut-col-legend = <(-10) 0 10 25 40 50>;
		qcom,lut-row-legend = <10000 9800 9600 9400 9200 9000>,
			<8800 8600 8400 8200 8000 7800>,
			<7600 7400 7200 7000 6800 6600>,
			<6400 6200 6000 5800 5600 5400>,
			<5200 5000 4800 4600 4400 4200>,
			<4000 3800 3600 3400 3200 3000>,
			<2800 2600 2400 2200 2000 1800>,
			<1600 1400 1200 1000 900 800>,
			<700 600 500 400 300 200>,
			<100 0>;
		qcom,lut-data = <6138 5510 5184 5045 5012 5010>,
			<6172 5529 5196 5045 5013 5012>,
			<6193 5551 5205 5046 5013 5014>,
			<6204 5571 5212 5046 5014 5017>,
			<6208 5585 5217 5047 5014 5019>,
			<6208 5591 5218 5047 5015 5020>,
			<6195 5589 5216 5048 5016 5021>,
			<6168 5584 5213 5049 5017 5021>,
			<6141 5578 5209 5050 5018 5021>,
			<6109 5570 5206 5051 5019 5021>,
			<6092 5563 5204 5053 5020 5021>,
			<6111 5559 5203 5054 5022 5022>,
			<6142 5556 5203 5056 5023 5023>,
			<6141 5559 5203 5059 5025 5025>,
			<6103 5580 5205 5062 5027 5028>,
			<6058 5594 5207 5066 5030 5030>,
			<6013 5576 5214 5069 5032 5033>,
			<5972 5542 5222 5074 5035 5035>,
			<5955 5522 5221 5080 5039 5040>,
			<5949 5510 5213 5088 5046 5047>,
			<5941 5498 5202 5091 5049 5050>,
			<5927 5484 5185 5079 5045 5045>,
			<5912 5471 5167 5063 5037 5036>,
			<5914 5461 5157 5051 5028 5027>,
			<5940 5453 5149 5042 5017 5017>,
			<5972 5447 5146 5039 5012 5013>,
			<6000 5440 5145 5039 5013 5013>,
			<6031 5435 5145 5040 5013 5013>,
			<6063 5438 5146 5041 5014 5014>,
			<6096 5465 5147 5044 5017 5017>,
			<6131 5498 5148 5047 5020 5020>,
			<6170 5532 5146 5050 5024 5024>,
			<6210 5570 5144 5053 5027 5027>,
			<6247 5612 5146 5054 5028 5028>,
			<6283 5660 5153 5056 5028 5029>,
			<6318 5713 5163 5056 5028 5029>,
			<6353 5773 5176 5054 5024 5024>,
			<6386 5840 5192 5051 5019 5019>,
			<6412 5908 5211 5050 5018 5017>,
			<6433 5978 5232 5049 5018 5016>,
			<6455 6048 5254 5049 5018 5016>,
			<6479 6113 5279 5054 5021 5019>,
			<6509 6177 5306 5056 5022 5020>,
			<6552 6241 5339 5055 5015 5014>,
			<6621 6310 5373 5057 5016 5014>,
			<6626 6287 5369 5060 5022 5021>,
			<6702 6348 5407 5068 5031 5029>,
			<6818 6427 5451 5078 5042 5040>,
			<6979 6515 5504 5090 5054 5052>,
			<7246 6598 5565 5099 5051 5048>,
			<8116 6716 5626 5082 5031 5028>,
			<10123 6916 5721 5082 5029 5024>,
			<15334 7730 5956 5100 5034 5026>,
			<32158 10525 6475 5125 5046 5039>,
			<32158 10525 6475 5125 5046 5039>,
			<32158 10525 6475 5125 5046 5039>;
	};

};
